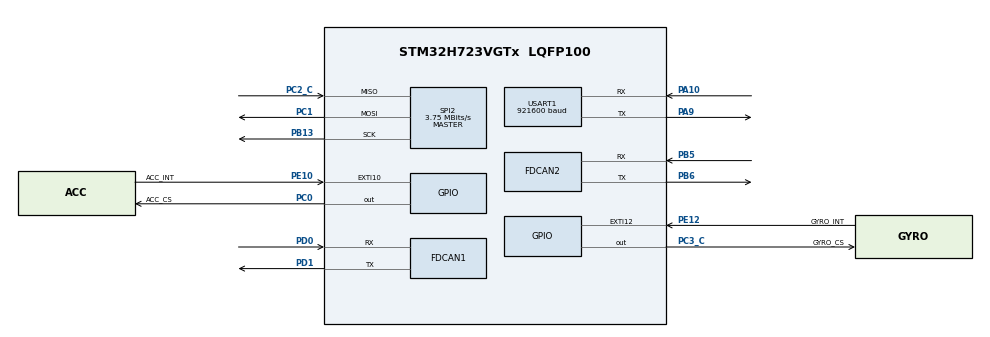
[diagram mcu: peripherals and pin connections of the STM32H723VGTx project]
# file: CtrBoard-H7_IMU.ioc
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Dma.Request0=SPI2_RX
Dma.Request1=SPI2_TX
Dma.Request2=USART1_TX
Dma.SPI2_RX.0.Direction=DMA_PERIPH_TO_MEMORY
Dma.SPI2_RX.0.EventEnable=DISABLE
Dma.SPI2_RX.0.FIFOMode=DMA_FIFOMODE_DISABLE
Dma.SPI2_RX.0.Instance=DMA1_Stream0
Dma.SPI2_RX.0.MemDataAlignment=DMA_MDATAALIGN_BYTE
Dma.SPI2_RX.0.MemInc=DMA_MINC_ENABLE
Dma.SPI2_RX.0.Mode=DMA_NORMAL
Dma.SPI2_RX.0.PeriphDataAlignment=DMA_PDATAALIGN_BYTE
Dma.SPI2_RX.0.PeriphInc=DMA_PINC_DISABLE
Dma.SPI2_RX.0.Polarity=HAL_DMAMUX_REQ_GEN_RISING
Dma.SPI2_RX.0.Priority=DMA_PRIORITY_VERY_HIGH
Dma.SPI2_RX.0.RequestNumber=1
Dma.SPI2_RX.0.SignalID=NONE
Dma.SPI2_RX.0.SyncEnable=DISABLE
Dma.SPI2_RX.0.SyncPolarity=HAL_DMAMUX_SYNC_NO_EVENT
Dma.SPI2_RX.0.SyncRequestNumber=1
Dma.SPI2_RX.0.SyncSignalID=NONE
Dma.SPI2_TX.1.Direction=DMA_MEMORY_TO_PERIPH
Dma.SPI2_TX.1.EventEnable=DISABLE
Dma.SPI2_TX.1.FIFOMode=DMA_FIFOMODE_DISABLE
Dma.SPI2_TX.1.Instance=DMA1_Stream1
Dma.SPI2_TX.1.MemDataAlignment=DMA_MDATAALIGN_BYTE
Dma.SPI2_TX.1.MemInc=DMA_MINC_ENABLE
Dma.SPI2_TX.1.Mode=DMA_NORMAL
Dma.SPI2_TX.1.PeriphDataAlignment=DMA_PDATAALIGN_BYTE
Dma.SPI2_TX.1.PeriphInc=DMA_PINC_DISABLE
Dma.SPI2_TX.1.Polarity=HAL_DMAMUX_REQ_GEN_RISING
Dma.SPI2_TX.1.Priority=DMA_PRIORITY_HIGH
Dma.SPI2_TX.1.RequestNumber=1
Dma.SPI2_TX.1.SignalID=NONE
Dma.SPI2_TX.1.SyncEnable=DISABLE
Dma.SPI2_TX.1.SyncPolarity=HAL_DMAMUX_SYNC_NO_EVENT
Dma.SPI2_TX.1.SyncRequestNumber=1
Dma.SPI2_TX.1.SyncSignalID=NONE
Dma.USART1_TX.2.Direction=DMA_MEMORY_TO_PERIPH
Dma.USART1_TX.2.EventEnable=DISABLE
Dma.USART1_TX.2.FIFOMode=DMA_FIFOMODE_DISABLE
Dma.USART1_TX.2.Instance=DMA1_Stream2
Dma.USART1_TX.2.MemDataAlignment=DMA_MDATAALIGN_BYTE
Dma.USART1_TX.2.MemInc=DMA_MINC_ENABLE
Dma.USART1_TX.2.Mode=DMA_NORMAL
Dma.USART1_TX.2.PeriphDataAlignment=DMA_PDATAALIGN_BYTE
Dma.USART1_TX.2.PeriphInc=DMA_PINC_DISABLE
Dma.USART1_TX.2.Polarity=HAL_DMAMUX_REQ_GEN_RISING
Dma.USART1_TX.2.Priority=DMA_PRIORITY_LOW
Dma.USART1_TX.2.RequestNumber=1
Dma.USART1_TX.2.SignalID=NONE
Dma.USART1_TX.2.SyncEnable=DISABLE
Dma.USART1_TX.2.SyncPolarity=HAL_DMAMUX_SYNC_NO_EVENT
Dma.USART1_TX.2.SyncRequestNumber=1
Dma.USART1_TX.2.SyncSignalID=NONE
FDCAN1.CalculateBaudRateNominal=1499999
FDCAN1.CalculateTimeBitNominal=666
FDCAN1.CalculateTimeQuantumNominal=133.33333333333334
FDCAN1.NominalPrescaler=16
FDCAN1.RxFifo0ElmtsNbr=32
FDCAN1.StdFiltersNbr=1
FDCAN2.CalculateBaudRateNominal=1000000
FDCAN2.CalculateTimeBitNominal=1000
FDCAN2.CalculateTimeQuantumNominal=200.0
FDCAN2.MessageRAMOffset=0x406
FDCAN2.NominalPrescaler=24
FDCAN2.RxFifo0ElmtsNbr=32
FDCAN2.StdFiltersNbr=1
FDCAN2.TxFifoQueueElmtsNbr=32
Mcu.Family=STM32H7
Mcu.Name=STM32H723VGTx
Mcu.Package=LQFP100
NVIC.DMA1_Stream0_IRQn=true\:1\:0\:true\:false\:true\:false\:true\:true
NVIC.DMA1_Stream1_IRQn=true\:2\:0\:true\:false\:true\:false\:true\:true
NVIC.DMA1_Stream2_IRQn=true\:0\:0\:false\:false\:true\:false\:true\:true
NVIC.FDCAN1_IT0_IRQn=true\:0\:0\:false\:false\:true\:true\:true\:true
NVIC.FDCAN1_IT1_IRQn=true\:0\:0\:false\:false\:true\:true\:true\:true
NVIC.FDCAN2_IT0_IRQn=true\:0\:0\:true\:false\:true\:true\:true\:true
NVIC.FDCAN2_IT1_IRQn=true\:0\:0\:true\:false\:true\:true\:true\:true
NVIC.PriorityGroup=NVIC_PRIORITYGROUP_4
NVIC.SPI2_IRQn=true\:5\:0\:true\:false\:true\:false\:true\:true
NVIC.TIM6_DAC_IRQn=true\:0\:0\:false\:false\:true\:true\:true\:true
NVIC.USART1_IRQn=true\:0\:0\:false\:false\:true\:true\:true\:true
PA10.Mode=Asynchronous
PA10.Signal=USART1_RX
PA13(JTMS/SWDIO).Mode=Serial_Wire
PA13(JTMS/SWDIO).Signal=DEBUG_JTMS-SWDIO
PA14(JTCK/SWCLK).Mode=Serial_Wire
PA14(JTCK/SWCLK).Signal=DEBUG_JTCK-SWCLK
PA9.Mode=Asynchronous
PA9.Signal=USART1_TX
PB13.GPIO_Speed=GPIO_SPEED_FREQ_VERY_HIGH
PB13.Mode=Full_Duplex_Master
PB13.Signal=SPI2_SCK
PB5.Mode=FDCAN_Activate
PB5.Signal=FDCAN2_RX
PB6.Mode=FDCAN_Activate
PB6.Signal=FDCAN2_TX
PC0.GPIO_Label=ACC_CS
PC0.GPIO_Speed=GPIO_SPEED_FREQ_VERY_HIGH
PC0.PinState=GPIO_PIN_SET
PC0.Signal=GPIO_Output
PC1.GPIO_Speed=GPIO_SPEED_FREQ_VERY_HIGH
PC1.Mode=Full_Duplex_Master
PC1.Signal=SPI2_MOSI
PC2_C.GPIO_Speed=GPIO_SPEED_FREQ_VERY_HIGH
PC2_C.Mode=Full_Duplex_Master
PC2_C.Signal=SPI2_MISO
PC3_C.GPIO_Label=GYRO_CS
PC3_C.GPIO_Speed=GPIO_SPEED_FREQ_VERY_HIGH
PC3_C.PinState=GPIO_PIN_SET
PC3_C.Signal=GPIO_Output
PD0.Mode=FDCAN_Activate
PD0.Signal=FDCAN1_RX
PD1.Mode=FDCAN_Activate
PD1.Signal=FDCAN1_TX
PE10.GPIO_Label=ACC_INT
PE10.Signal=GPXTI10
PE12.GPIO_Label=GYRO_INT
PE12.Signal=GPXTI12
PH0-OSC_IN.Mode=HSE-External-Oscillator
PH0-OSC_IN.Signal=RCC_OSC_IN
PH1-OSC_OUT.Mode=HSE-External-Oscillator
PH1-OSC_OUT.Signal=RCC_OSC_OUT
ProjectManager.HeapSize=0x200
ProjectManager.StackSize=0x800
ProjectManager.TargetToolchain=MDK-ARM V5.27
RCC.ADCFreq_Value=48375000
RCC.APB1Freq_Value=120000000
RCC.APB2Freq_Value=120000000
RCC.APB3Freq_Value=120000000
RCC.APB4Freq_Value=120000000
RCC.CortexFreq_Value=480000000
RCC.D1PPRE=RCC_APB3_DIV2
RCC.D2PPRE1=RCC_APB1_DIV2
RCC.D2PPRE2=RCC_APB2_DIV2
RCC.D3PPRE=RCC_APB4_DIV2
RCC.DIVM1=2
RCC.DIVN1=40
RCC.DIVP1=1
RCC.DIVQ1=4
RCC.HCLKFreq_Value=240000000
RCC.HPRE=RCC_HCLK_DIV2
RCC.HSE_VALUE=24000000
RCC.PLL2FRACN=0
RCC.PLL3FRACN=0
RCC.PLLFRACN=0
RCC.PLLSourceVirtual=RCC_PLLSOURCE_HSE
RCC.SYSCLKFreq_VALUE=480000000
RCC.SYSCLKSource=RCC_SYSCLKSOURCE_PLLCLK
RCC.USBFreq_Value=120000000
SPI2.BaudRatePrescaler=SPI_BAUDRATEPRESCALER_32
SPI2.CLKPhase=SPI_PHASE_2EDGE
SPI2.CLKPolarity=SPI_POLARITY_HIGH
SPI2.CalculateBaudRate=3.75 MBits/s
SPI2.DataSize=SPI_DATASIZE_8BIT
SPI2.Direction=SPI_DIRECTION_2LINES
SPI2.Mode=SPI_MODE_MASTER
SPI2.VirtualType=VM_MASTER
TIM6.Period=2000
TIM6.Prescaler=42-1
USART1.BaudRate=921600
USART1.VirtualMode-Asynchronous=VM_ASYNC
VP_MEMORYMAP_VS_MEMORYMAP.Mode=CurAppReg
VP_TIM6_VS_ClockSourceINT.Mode=Enable_Timer
board=custom

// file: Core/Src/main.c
#include "main.h"
#include "dma.h"
#include "fdcan.h"
#include "memorymap.h"
#include "spi.h"
#include "tim.h"
#include "usart.h"
#include "gpio.h"

#include "BMI088driver.h"
#include "dm_driver.h"

extern float pos[];//pos[0] is unused, start from pos[1]
extern float vel[];
float kp[11]={20,20,20,20,20,20,20,20,20,20,20};
float kd[11]={0.2,0.2,0.2,0.2,0.2,0.2,0.2,0.2,0.2,0.2,0.2};
float torq[11]={0,0,0,0,0,0,0,0,0,0,0};

void SystemClock_Config(void);

/* USER CODE BEGIN 0 */
float gyro[3], accel[3], temp;
/* USER CODE END 0 */

int main(void)
{

  /* MCU Configuration--------------------------------------------------------*/

  /* Reset of all peripherals, Initializes the Flash interface and the Systick. */
  HAL_Init();

  /* Configure the system clock */
  SystemClock_Config();

  /* Initialize all configured peripherals */
  MX_GPIO_Init();
  MX_DMA_Init();
  MX_SPI2_Init();
  MX_USART1_UART_Init();
  MX_FDCAN1_Init();
  MX_FDCAN2_Init();
  MX_TIM6_Init();
  /* USER CODE BEGIN 2 */
	can_bsp_init();
	enable_motor_mode(&hfdcan2,1,MIT_MODE);
	HAL_Delay(100);
    enable_motor_mode(&hfdcan2,2,MIT_MODE);
	HAL_Delay(100);
	enable_motor_mode(&hfdcan2,3,MIT_MODE);
	HAL_Delay(100);
    enable_motor_mode(&hfdcan2,4,MIT_MODE);
	HAL_Delay(100);
	enable_motor_mode(&hfdcan2,5,MIT_MODE);
	HAL_Delay(100);
	enable_motor_mode(&hfdcan1,6,MIT_MODE);
	HAL_Delay(100);
    enable_motor_mode(&hfdcan1,7,MIT_MODE);
	HAL_Delay(100);
	enable_motor_mode(&hfdcan1,8,MIT_MODE);
	HAL_Delay(100);
    enable_motor_mode(&hfdcan1,9,MIT_MODE);
	HAL_Delay(100);
	enable_motor_mode(&hfdcan1,10,MIT_MODE);
	HAL_Delay(100);
    while(BMI088_init())
    {

    }
		HAL_TIM_Base_Start_IT(&htim6);
	while (1)
	{

	}
}

void SystemClock_Config(void)
{
  RCC_OscInitTypeDef RCC_OscInitStruct = {0};
  RCC_ClkInitTypeDef RCC_ClkInitStruct = {0};

  /** Supply configuration update enable
  */
  HAL_PWREx_ConfigSupply(PWR_LDO_SUPPLY);

  /** Configure the main internal regulator output voltage
  */
  __HAL_PWR_VOLTAGESCALING_CONFIG(PWR_REGULATOR_VOLTAGE_SCALE0);

  while(!__HAL_PWR_GET_FLAG(PWR_FLAG_VOSRDY)) {}

  /** Initializes the RCC Oscillators according to the specified parameters
  * in the RCC_OscInitTypeDef structure.
  */
  RCC_OscInitStruct.OscillatorType = RCC_OSCILLATORTYPE_HSE;
  RCC_OscInitStruct.HSEState = RCC_HSE_ON;
  RCC_OscInitStruct.PLL.PLLState = RCC_PLL_ON;
  RCC_OscInitStruct.PLL.PLLSource = RCC_PLLSOURCE_HSE;
  RCC_OscInitStruct.PLL.PLLM = 2;
  RCC_OscInitStruct.PLL.PLLN = 40;
  RCC_OscInitStruct.PLL.PLLP = 1;
  RCC_OscInitStruct.PLL.PLLQ = 4;
  RCC_OscInitStruct.PLL.PLLR = 2;
  RCC_OscInitStruct.PLL.PLLRGE = RCC_PLL1VCIRANGE_3;
  RCC_OscInitStruct.PLL.PLLVCOSEL = RCC_PLL1VCOWIDE;
  RCC_OscInitStruct.PLL.PLLFRACN = 0;
  if (HAL_RCC_OscConfig(&RCC_OscInitStruct) != HAL_OK)
  {
    Error_Handler();
  }

  /** Initializes the CPU, AHB and APB buses clocks
  */
  RCC_ClkInitStruct.ClockType = RCC_CLOCKTYPE_HCLK|RCC_CLOCKTYPE_SYSCLK
                              |RCC_CLOCKTYPE_PCLK1|RCC_CLOCKTYPE_PCLK2
                              |RCC_CLOCKTYPE_D3PCLK1|RCC_CLOCKTYPE_D1PCLK1;
  RCC_ClkInitStruct.SYSCLKSource = RCC_SYSCLKSOURCE_PLLCLK;
  RCC_ClkInitStruct.SYSCLKDivider = RCC_SYSCLK_DIV1;
  RCC_ClkInitStruct.AHBCLKDivider = RCC_HCLK_DIV2;
  RCC_ClkInitStruct.APB3CLKDivider = RCC_APB3_DIV2;
  RCC_ClkInitStruct.APB1CLKDivider = RCC_APB1_DIV2;
  RCC_ClkInitStruct.APB2CLKDivider = RCC_APB2_DIV2;
  RCC_ClkInitStruct.APB4CLKDivider = RCC_APB4_DIV2;

  if (HAL_RCC_ClockConfig(&RCC_ClkInitStruct, FLASH_LATENCY_3) != HAL_OK)
  {
    Error_Handler();
  }
}

void Error_Handler(void)
{
  __disable_irq();
  while (1)
  {
  }
}
